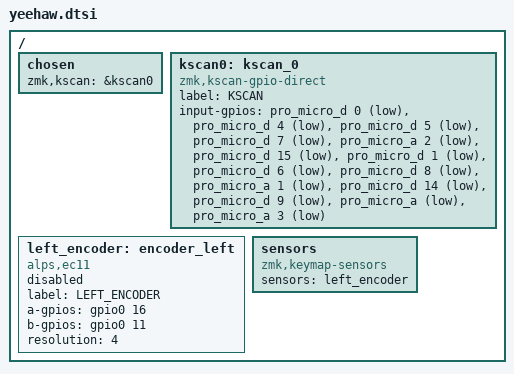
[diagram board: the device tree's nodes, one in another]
#include <dt-bindings/zmk/matrix-transform.h>

/ {
	chosen {
		zmk,kscan = &kscan0;
	};
	kscan0: kscan_0 {
		compatible = "zmk,kscan-gpio-direct";

		label = "KSCAN";

		input-gpios
			= <&pro_micro_d 0 (GPIO_ACTIVE_LOW | GPIO_PULL_UP)>
			, <&pro_micro_d 4 (GPIO_ACTIVE_LOW | GPIO_PULL_UP)>
			, <&pro_micro_d 5 (GPIO_ACTIVE_LOW | GPIO_PULL_UP)>
			, <&pro_micro_d 7 (GPIO_ACTIVE_LOW | GPIO_PULL_UP)>
			, <&pro_micro_a 2 (GPIO_ACTIVE_LOW | GPIO_PULL_UP)>
			, <&pro_micro_d 15 (GPIO_ACTIVE_LOW | GPIO_PULL_UP)>
			, <&pro_micro_d 1 (GPIO_ACTIVE_LOW | GPIO_PULL_UP)>
			, <&pro_micro_d 6 (GPIO_ACTIVE_LOW | GPIO_PULL_UP)>
			, <&pro_micro_d 8 (GPIO_ACTIVE_LOW | GPIO_PULL_UP)>
			, <&pro_micro_a 1 (GPIO_ACTIVE_LOW | GPIO_PULL_UP)>
			, <&pro_micro_d 14 (GPIO_ACTIVE_LOW | GPIO_PULL_UP)>
			, <&pro_micro_d 9 (GPIO_ACTIVE_LOW | GPIO_PULL_UP)>
			, <&pro_micro_a 0(GPIO_ACTIVE_LOW | GPIO_PULL_UP)>
			, <&pro_micro_a 3 (GPIO_ACTIVE_LOW | GPIO_PULL_UP)>
			;
	};

	left_encoder: encoder_left {
		compatible = "alps,ec11";
		label = "LEFT_ENCODER";
		a-gpios = <&gpio0 16 (GPIO_ACTIVE_HIGH | GPIO_PULL_UP)>;
		b-gpios = <&gpio0 11 (GPIO_ACTIVE_HIGH | GPIO_PULL_UP)>;
		resolution = <4>;
		status = "enabled";
	};

	sensors {
		compatible = "zmk,keymap-sensors";
		sensors = <&left_encoder>;
	};
};

